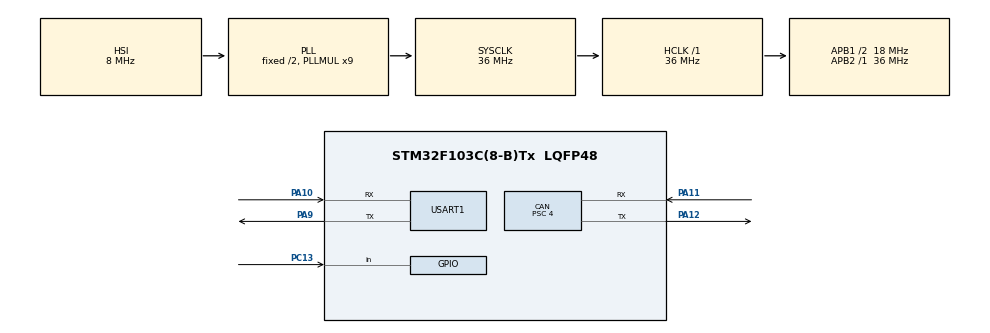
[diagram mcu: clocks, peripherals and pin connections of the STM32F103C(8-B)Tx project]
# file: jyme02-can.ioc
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CAN.BS1=CAN_BS1_11TQ
CAN.BS2=CAN_BS2_6TQ
CAN.CalculateBaudRate=250000
CAN.CalculateTimeBit=4000
CAN.CalculateTimeQuantum=222.22222222222223
CAN.Mode=CAN_MODE_NORMAL
CAN.Prescaler=4
CAN.RFLM=ENABLE
Mcu.Family=STM32F1
Mcu.Name=STM32F103C(8-B)Tx
Mcu.Package=LQFP48
NVIC.PriorityGroup=NVIC_PRIORITYGROUP_4
NVIC.USB_LP_CAN1_RX0_IRQn=true\:0\:0\:false\:false\:true\:true\:true\:true
PA10.Mode=Asynchronous
PA10.Signal=USART1_RX
PA11.Mode=CAN_Activate
PA11.Signal=CAN_RX
PA12.Mode=CAN_Activate
PA12.Signal=CAN_TX
PA13.Mode=Serial_Wire
PA13.Signal=SYS_JTMS-SWDIO
PA14.Mode=Serial_Wire
PA14.Signal=SYS_JTCK-SWCLK
PA9.Mode=Asynchronous
PA9.Signal=USART1_TX
PC13-TAMPER-RTC.Signal=GPIO_Input
PD0-OSC_IN.Mode=HSE-External-Oscillator
PD0-OSC_IN.Signal=RCC_OSC_IN
PD1-OSC_OUT.Mode=HSE-External-Oscillator
PD1-OSC_OUT.Signal=RCC_OSC_OUT
ProjectManager.HeapSize=0x200
ProjectManager.StackSize=0x400
ProjectManager.TargetToolchain=MDK-ARM V5.32
RCC.AHBFreq_Value=36000000
RCC.APB1CLKDivider=RCC_HCLK_DIV2
RCC.APB1Freq_Value=18000000
RCC.APB1TimFreq_Value=36000000
RCC.APB2Freq_Value=36000000
RCC.APB2TimFreq_Value=36000000
RCC.HCLKFreq_Value=36000000
RCC.PLLMUL=RCC_PLL_MUL9
RCC.SYSCLKFreq_VALUE=36000000
RCC.SYSCLKSource=RCC_SYSCLKSOURCE_PLLCLK
RCC.USBFreq_Value=36000000
USART1.VirtualMode=VM_ASYNC
board=custom

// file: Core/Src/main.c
/* USER CODE BEGIN Header */
/**
 ******************************************************************************
 * @file           : main.c
 * @brief          : Main program body
 ******************************************************************************
 * @attention
 *
 * Copyright (c) 2023 STMicroelectronics.
 * All rights reserved.
 *
 * This software is licensed under terms that can be found in the LICENSE file
 * in the root directory of this software component.
 * If no LICENSE file comes with this software, it is provided AS-IS.
 *
 ******************************************************************************
 */
/* USER CODE END Header */
#include "main.h"

/* USER CODE BEGIN Includes */
#include "..\..\JYME02-CAN-Core\jyme02_can.hpp"
/* USER CODE END Includes */

CAN_HandleTypeDef hcan;

UART_HandleTypeDef huart1;

void SystemClock_Config(void);
static void MX_GPIO_Init(void);
static void MX_CAN_Init(void);
static void MX_USART1_UART_Init(void);

int main(void)
{

    /* MCU Configuration--------------------------------------------------------*/

    /* Reset of all peripherals, Initializes the Flash interface and the Systick. */
    HAL_Init();

    /* Configure the system clock */
    SystemClock_Config();

    /* Initialize all configured peripherals */
    MX_GPIO_Init();
    MX_CAN_Init();
    MX_USART1_UART_Init();
    /* USER CODE BEGIN 2 */
    Jyme02_Can_Init(&hcan, CAN_FILTER_FIFO0);
    /* USER CODE END 2 */

    /* Infinite loop */
    /* USER CODE BEGIN WHILE */
    while (1) {
        HAL_Delay(100);
        if (HAL_GPIO_ReadPin(GPIOC, GPIO_PIN_13) != GPIO_PIN_SET) {
            Jyme02_Can_Set_Addr(0x50, 0x61);
        }

        /* USER CODE END WHILE */

    }
}

void SystemClock_Config(void)
{
    RCC_OscInitTypeDef RCC_OscInitStruct = {0};
    RCC_ClkInitTypeDef RCC_ClkInitStruct = {0};

    /** Initializes the RCC Oscillators according to the specified parameters
     * in the RCC_OscInitTypeDef structure.
     */
    RCC_OscInitStruct.OscillatorType      = RCC_OSCILLATORTYPE_HSI;
    RCC_OscInitStruct.HSIState            = RCC_HSI_ON;
    RCC_OscInitStruct.HSICalibrationValue = RCC_HSICALIBRATION_DEFAULT;
    RCC_OscInitStruct.PLL.PLLState        = RCC_PLL_ON;
    RCC_OscInitStruct.PLL.PLLSource       = RCC_PLLSOURCE_HSI_DIV2;
    RCC_OscInitStruct.PLL.PLLMUL          = RCC_PLL_MUL9;
    if (HAL_RCC_OscConfig(&RCC_OscInitStruct) != HAL_OK) {
        Error_Handler();
    }

    /** Initializes the CPU, AHB and APB buses clocks
     */
    RCC_ClkInitStruct.ClockType      = RCC_CLOCKTYPE_HCLK | RCC_CLOCKTYPE_SYSCLK | RCC_CLOCKTYPE_PCLK1 | RCC_CLOCKTYPE_PCLK2;
    RCC_ClkInitStruct.SYSCLKSource   = RCC_SYSCLKSOURCE_PLLCLK;
    RCC_ClkInitStruct.AHBCLKDivider  = RCC_SYSCLK_DIV1;
    RCC_ClkInitStruct.APB1CLKDivider = RCC_HCLK_DIV2;
    RCC_ClkInitStruct.APB2CLKDivider = RCC_HCLK_DIV1;

    if (HAL_RCC_ClockConfig(&RCC_ClkInitStruct, FLASH_LATENCY_1) != HAL_OK) {
        Error_Handler();
    }
}

static void MX_CAN_Init(void)
{

    hcan.Instance                  = CAN1;
    hcan.Init.Prescaler            = 4;
    hcan.Init.Mode                 = CAN_MODE_NORMAL;
    hcan.Init.SyncJumpWidth        = CAN_SJW_1TQ;
    hcan.Init.TimeSeg1             = CAN_BS1_11TQ;
    hcan.Init.TimeSeg2             = CAN_BS2_6TQ;
    hcan.Init.TimeTriggeredMode    = DISABLE;
    hcan.Init.AutoBusOff           = DISABLE;
    hcan.Init.AutoWakeUp           = DISABLE;
    hcan.Init.AutoRetransmission   = DISABLE;
    hcan.Init.ReceiveFifoLocked    = ENABLE;
    hcan.Init.TransmitFifoPriority = DISABLE;
    if (HAL_CAN_Init(&hcan) != HAL_OK) {
        Error_Handler();
    }
}

static void MX_USART1_UART_Init(void)
{

    huart1.Instance          = USART1;
    huart1.Init.BaudRate     = 115200;
    huart1.Init.WordLength   = UART_WORDLENGTH_8B;
    huart1.Init.StopBits     = UART_STOPBITS_1;
    huart1.Init.Parity       = UART_PARITY_NONE;
    huart1.Init.Mode         = UART_MODE_TX_RX;
    huart1.Init.HwFlowCtl    = UART_HWCONTROL_NONE;
    huart1.Init.OverSampling = UART_OVERSAMPLING_16;
    if (HAL_UART_Init(&huart1) != HAL_OK) {
        Error_Handler();
    }
}

static void MX_GPIO_Init(void)
{
    GPIO_InitTypeDef GPIO_InitStruct = {0};

    /* GPIO Ports Clock Enable */
    __HAL_RCC_GPIOC_CLK_ENABLE();
    __HAL_RCC_GPIOD_CLK_ENABLE();
    __HAL_RCC_GPIOA_CLK_ENABLE();

    /*Configure GPIO pin : PC13 */
    GPIO_InitStruct.Pin  = GPIO_PIN_13;
    GPIO_InitStruct.Mode = GPIO_MODE_INPUT;
    GPIO_InitStruct.Pull = GPIO_NOPULL;
    HAL_GPIO_Init(GPIOC, &GPIO_InitStruct);

}

/* USER CODE BEGIN 4 */
void HAL_CAN_RxFifo0MsgPendingCallback(CAN_HandleTypeDef *hcan)
{
    /* Prevent unused argument(s) compilation warning */
    float angle;
    uint16_t addr;
    if (hcan->Instance == CAN1) {
        angle = Jyme02_Can_Read_AngleMode(&addr);
        HAL_UART_Transmit(&huart1, (uint8_t *)&angle, 4, 1);
    }
    /* NOTE : This function Should not be modified, when the callback is needed,
              the HAL_CAN_TxMailbox0AbortCallback could be implemented in the
              user file
     */
}
/* USER CODE END 4 */

void Error_Handler(void)
{
    __disable_irq();
    while (1) {
    }
}
